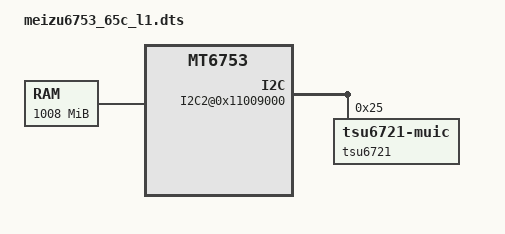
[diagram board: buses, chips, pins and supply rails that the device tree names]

/dts-v1/;

/include/ "mt6753.dtsi"

/ {
  memory@00000000 {
		device_type = "memory";
		reg = <0 0x40000000 0 0x3F000000>;
	};

	bus {
		compatible = "simple-bus";
		#address-cells = <1>;
		#size-cells = <1>;
		ranges = <0 0 0 0xffffffff>;

		MTKFB@5e200000 {
			compatible = "mediatek,MTKFB";
			reg = <0x7F000000 0x1000000>;
		};

        I2C2@0x11009000 {
            #address-cells = <1>;
            #size-cells = <0>;
             tsu6721@25 {
                compatible = "tsu6721-muic";
                reg = <0x25>;
            };
        };

	};


};
